AUTOSAR XML (schema 4-2-1)
package /ComponentTypes
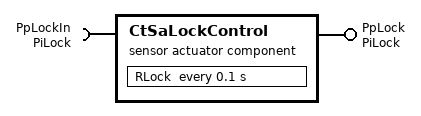
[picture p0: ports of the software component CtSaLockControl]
  sensor actuator sw component type CtSaLockControl
    provide port PpLock: nonqueued-sender-com-spec{data-element=DeLock, init-value=constant-reference=CCarLocked}, provided-interface=PiLock
    require port PpLockIn: nonqueued-receiver-com-spec{data-element=DeLock, filter=data-filter-type=ALWAYS, init-value=constant-reference=CCarLocked}, required-interface=PiLock
    behavior CtSaLockControl_InternalBehavior: data-type-mapping=ApMappingSet
      timing event TMT_RLock: start-on-event=RLock, period=0.1
      runnable RLock
        data-receive-point-by-arguments:
          access REC_PpLockIn_DeLock: accessed-variable=PpLockIn.DeLock
        data-send-points:
          access SEND_PpLock_DeLock: accessed-variable=PpLock.DeLock
  swc implementation CtSaLockControl_Implementation: behavior=CtSaLockControl_InternalBehavior
    code-descriptors:
      code Default: artifact-descriptors=autosar-engineering-object={short-label=Default, category=SWSRC}
